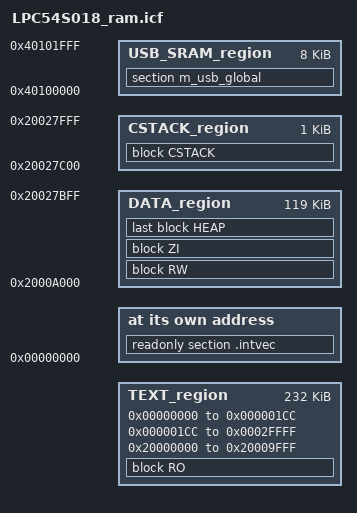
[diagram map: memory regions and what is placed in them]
/*
** ###################################################################
**     Processors:          LPC54S018JBD208
**                          LPC54S018JET180
**
**     Compiler:            IAR ANSI C/C++ Compiler for ARM
**     Reference manual:    LPC540xx/LPC54S0xx User manual Rev.0.7 20 April 2018
**     Version:             rev. 1.2, 2017-06-08
**     Build:               b170823
**
**     Abstract:
**         Linker file for the IAR ANSI C/C++ Compiler for ARM
**
**     Copyright 2016 Freescale Semiconductor, Inc.
**     Copyright 2016-2017 NXP
**     All rights reserved.
**     
**     SPDX-License-Identifier: BSD-3-Clause
**
**     http:                 www.nxp.com
**     mail:                 support@nxp.com
**
** ###################################################################
*/


/* USB BDT size */
define symbol usb_bdt_size             = 0x0;
/* Stack and Heap Sizes */
if (isdefinedsymbol(__stack_size__)) {
  define symbol __size_cstack__        = __stack_size__;
} else {
  define symbol __size_cstack__        = 0x0400;
}

if (isdefinedsymbol(__heap_size__)) {
  define symbol __size_heap__          = __heap_size__;
} else {
  define symbol __size_heap__          = 0x0800;
}

define symbol m_interrupts_start               = 0x00000000;
define symbol m_interrupts_end                 = 0x000001CC;

define symbol m_text_start                     = 0x000001CC;
define symbol m_text_end                       = 0x0002FFFF;

define symbol m_text2_start                    = 0x20000000;
define symbol m_text2_end                      = 0x20009FFF;

define symbol m_data_start                     = 0x2000A000;
define symbol m_data_end                       = 0x20027FFF - __size_cstack__;

define symbol m_stack_start                    = 0x20028000 - __size_cstack__;
define symbol m_stack_end                      = 0x20027FFF;

define symbol m_usb_sram_start                 = 0x40100000;
define symbol m_usb_sram_end                   = 0x40101FFF;

define memory mem with size = 4G;

define region TEXT_region             = mem:[from m_interrupts_start to m_interrupts_end]
                                      | mem:[from m_text_start to m_text_end] | mem:[from m_text2_start to m_text2_end];
define region DATA_region             = mem:[from m_data_start to m_stack_start - 1];
define region CSTACK_region           = mem:[from m_stack_start to m_stack_end];

define block CSTACK    with alignment = 8, size = __size_cstack__   { };
define block HEAP      with alignment = 8, size = __size_heap__     { };
define block RO        { readonly };
define block RW        { readwrite };
define block ZI        { zi };

/* regions for USB */
define region USB_BDT_region = mem:[from m_usb_sram_start to m_usb_sram_start + usb_bdt_size - 1];
define region USB_SRAM_region = mem:[from m_usb_sram_start + usb_bdt_size to m_usb_sram_end];
place in USB_BDT_region                     { section m_usb_bdt };
place in USB_SRAM_region                    { section m_usb_global };

initialize by copy { readwrite, section .textrw };

if (isdefinedsymbol(__USE_DLIB_PERTHREAD))
{
  /* Required in a multi-threaded application */
  initialize by copy with packing = none { section __DLIB_PERTHREAD };
}

do not initialize  { section .noinit, section m_usb_bdt, section m_usb_global };

place at address mem: m_interrupts_start    { readonly section .intvec };
place in TEXT_region                        { block RO };
place in DATA_region                        { block RW };
place in DATA_region                        { block ZI };
place in DATA_region                        { last block HEAP };
place in CSTACK_region                      { block CSTACK };
